# XMC4700 register map
Vendor: Infineon; File version: 1.3.0 (Reference Manual v1.3)
CPU: CM4 r2p0, little endian, MPU, FPU, 6 interrupt priority bits
Registers are 32-bit, read-write, reset 0x0 unless marked. A register's access mark holds for its fields unless they carry their own. Offsets are from the block's base; [hi:lo] are bit positions; {n}, {i} and the like mark numbered series.

## CAN — Controller Area Networks
Base 0x48014000
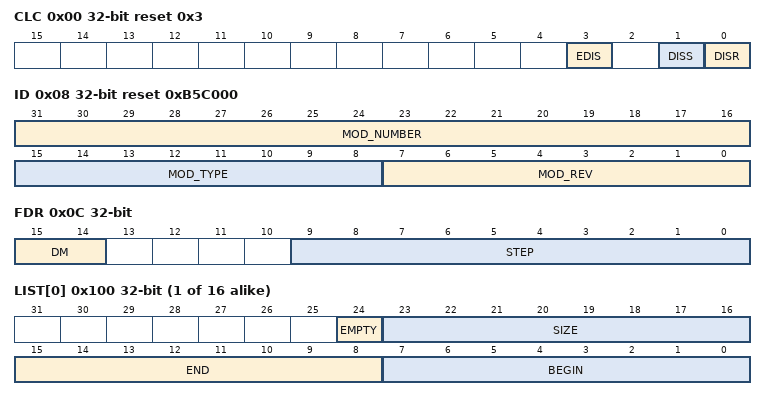
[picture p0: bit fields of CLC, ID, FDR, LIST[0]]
0x00 CLC access per field reset 0x3 — CAN Clock Control Register
  [3] EDIS rw — Sleep Mode Enable Control
  [1] DISS ro — Module Disable Status Bit
  [0] DISR rw — Module Disable Request Bit
0x08 ID ro reset 0xB5C000 (reset mask 0xFFFFFF00) — Module Identification Register
  [31:16] MOD_NUMBER — Module Number Value
  [15:8] MOD_TYPE — Module Type
    192=Define the module as a 32-bit module
  [7:0] MOD_REV — Module Revision Number
0x0C FDR — CAN Fractional Divider Register
  [15:14] DM — Divider Mode
  [9:0] STEP — Step Value
{0x100+4i} LIST[{i}] (i=0..15) ro reset not defined
  [24] EMPTY — List Empty Indication
    0=At least one message object is allocated to list i; 1=No message object is allocated to the list i. List i is empty.
  [23:16] SIZE — List Size
  [15:8] END — List End
  [7:0] BEGIN — List Begin
{0x140+4i} MSPND[{i}] (i=0..7) — Message Pending Register
  [31:0] PND — Message Pending
{0x180+4i} MSID[{i}] (i=0..7) ro reset 0x20 — Message Index Register
  [5:0] INDEX — Message Pending Index
0x1C0 MSIMASK — Message Index Mask Register
  [31:0] IM — Message Index Mask
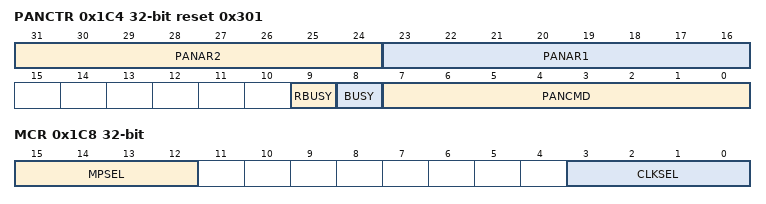
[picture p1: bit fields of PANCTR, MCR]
0x1C4 PANCTR access per field reset 0x301 — Panel Control Register
  [31:24] PANAR2 rw — Panel Argument 2
  [23:16] PANAR1 rw — Panel Argument 1
  [9] RBUSY ro — Result Busy Flag
    0=No update of PANAR1 and PANAR2 is scheduled by the list controller; 1=A list command is running (BUSY = 1) that will write results to PANAR1 and PANAR2, but the results are not yet available
  [8] BUSY ro — Panel Busy Flag
    0=Panel has finished command and is ready to accept a new command; 1=Panel operation is in progress
  [7:0] PANCMD rw — Panel Command
0x1C8 MCR — Module Control Register
  [15:12] MPSEL — Message Pending Selector
  [3:0] CLKSEL — Baud Rate Logic Clock Select
    0=No clock supplied; 1=fPERIPH; 2=fOHP; 4=hard wired to 0; 8=hard wired to 0
0x1CC MITR wo — Module Interrupt Trigger Register
  [7:0] IT — Interrupt Trigger

## DSD — Delta Sigma Demodulator
Base 0x40008000
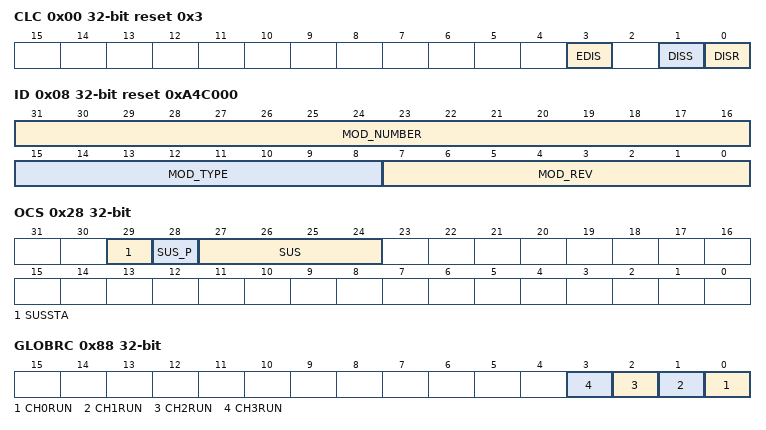
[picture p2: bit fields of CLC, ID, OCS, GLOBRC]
0x00 CLC access per field reset 0x3 — Clock Control Register
  [3] EDIS rw — Sleep Mode Enable Control
    0=Sleep mode request is enabled and functional; 1=Module disregards the sleep mode control signal
  [1] DISS ro — Module Disable Status Bit
    0=Module clock is enabled; 1=Off: module is not clocked
  [0] DISR rw — Module Disable Request Bit
    0=On request: enable the module clock; 1=Off request: stop the module clock
0x08 ID ro reset 0xA4C000 (reset mask 0xFFFFFF00) — Module Identification Register
  [31:16] MOD_NUMBER — Module Number
  [15:8] MOD_TYPE — Module Type
  [7:0] MOD_REV — Module Revision
0x28 OCS access per field — OCDS Control and Status Register
  [29] SUSSTA ro — Suspend State
    0=Module is not (yet) suspended; 1=Module is suspended
  [28] SUS_P wo — SUS Write Protection
  [27:24] SUS rw — OCDS Suspend Control
    0=Will not suspend; 1=Hard suspend: Clock is switched off immediately; 2=Soft suspend channel 0; 3=Soft suspend channel 1; 5=Soft suspend channel 3
0x80 GLOBCFG — Global Configuration Register
  [2:0] MCSEL — Modulator Clock Select
    0=Internal clock off, no source selected; 1=fDSD
0x88 GLOBRC — Global Run Control Register
  [all] fields
    0=Stop channel x; 1=Demodulator channel x is enabled and runs
  [n] CH{n}RUN (n=0..3) — Channel {n} Run Control
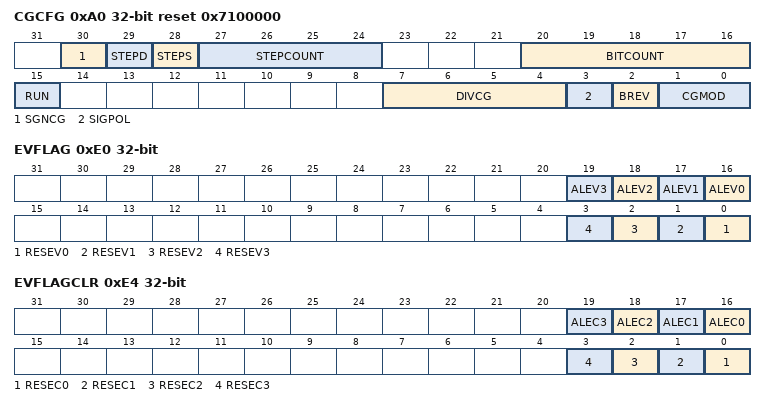
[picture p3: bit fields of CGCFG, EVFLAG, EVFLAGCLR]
0xA0 CGCFG access per field reset 0x7100000 — Carrier Generator Configuration Register
  [30] SGNCG ro — Sign Signal from Carrier Generator
    0=Positive values; 1=Negative values
  [29] STEPD ro — Step Counter Direction
    0=Step counter is counting up; 1=Step counter is counting down
  [28] STEPS ro — Step Counter Sign
    0=Step counter value is positive; 1=Step counter value is negative
  [27:24] STEPCOUNT ro — Step Counter
  [20:16] BITCOUNT ro — Bit Counter
  [15] RUN ro — Run Indicator
    0=Stopped (cleared at the end of a period); 1=Running
  [7:4] DIVCG rw — Divider Factor for the PWM Pattern Signal Generator
    0=fCG = fCLK / 2; 1=fCG = fCLK / 4; 2=fCG = fCLK / 6; 15=fCG = fCLK / 32
  [3] SIGPOL rw — Signal Polarity
    0=Normal: carrier signal begins with +1; 1=Inverted: carrier signal begins with -1
  [2] BREV rw — Bit-Reverse PWM Generation
    0=Normal mode; 1=Bit-reverse mode
  [1:0] CGMOD rw — Carrier Generator Operating Mode
    0=Stopped; 1=Square wave; 2=Triangle; 3=Sine wave
0xE0 EVFLAG — Event Flag Register
  [n+16] ALEV{n} (n=0..3) — Alarm Event
    0=No alarm event; 1=An alarm event has occurred
  [n] RESEV{n} (n=0..3) — Result Event
    0=No result event; 1=A new result has been stored in register RESMx
0xE4 EVFLAGCLR wo — Event Flag Clear Register
  [n+16] ALEC{n} (n=0..3) — Alarm Event Clear
    0=No action; 1=Clear bit ALEVx
  [n] RESEC{n} (n=0..3) — Result Event Clear
    0=No action; 1=Clear bit RESEVx

## CCU40 — Capture Compare Unit 4 - Unit 0
Base 0x4000C000
Same registers: CCU41 0x40010000, CCU42 0x40014000, CCU43 0x48004000
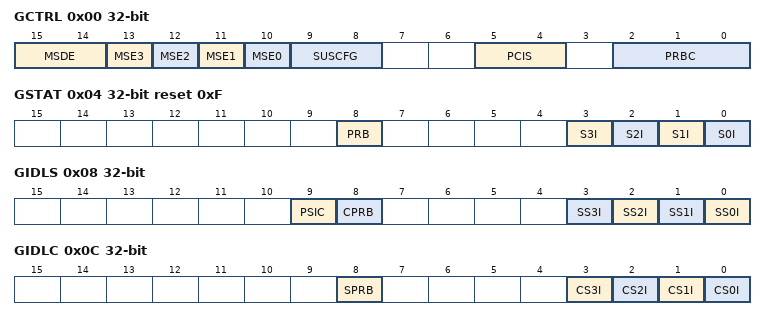
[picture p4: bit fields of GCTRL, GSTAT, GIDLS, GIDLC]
0x00 GCTRL — Global Control Register
  [15:14] MSDE — Multi Channel shadow transfer request configuration
    0=Only the shadow transfer for period and compare values is requested; 1=Shadow transfer for the compare, period and prescaler compare values is requested; 3=Shadow transfer for the compare, period, prescaler and dither compare values is requested
  [n+10] MSE{n} (n=0..3) — Slice {n} Multi Channel shadow transfer enable
    0=Shadow transfer can only be requested by SW; 1=Shadow transfer can be requested via SW and via the CCU4x.MCSS input
  [9:8] SUSCFG — Suspend Mode Configuration
    0=Suspend request ignored. The module never enters in suspend; 1=Stops all the running slices immediately. Safe stop is not applied.; 2=Stops the block immediately and clamps all the outputs to PASSIVE state. Safe stop is applied.; 3=Waits for the roll over of each slice to stop and clamp the slices outputs. Safe stop is applied.
  [5:4] PCIS — Prescaler Input Clock Selection
    0=Module clock; 1=CCU4x.ECLKA; 2=CCU4x.ECLKB; 3=CCU4x.ECLKC
  [2:0] PRBC — Prescaler Clear Configuration
    0=SW only; {v}=GSTATThe register contains the status of the prescaler and each timer slice (idle mode or running)..PRB and prescaler registers are cleared when the Run Bit of CC{v+39} is cleared (v=1..4)
0x04 GSTAT ro reset 0xF — Global Status Register
  [8] PRB — Prescaler Run Bit
    0=Prescaler is stopped; 1=Prescaler is running
  [n] S{n}I (n=0..3) — CC{n+40} IDLE status
    0=Running; 1=Idle
0x08 GIDLS wo — Global Idle Set
  [9] PSIC — Prescaler clear
  [8] CPRB — Prescaler Run Bit Clear
  [n] SS{n}I (n=0..3) — CC{n+40} IDLE mode set
0x0C GIDLC wo — Global Idle Clear
  [8] SPRB — Prescaler Run Bit Set
  [n] CS{n}I (n=0..3) — CC{n+40} IDLE mode clear
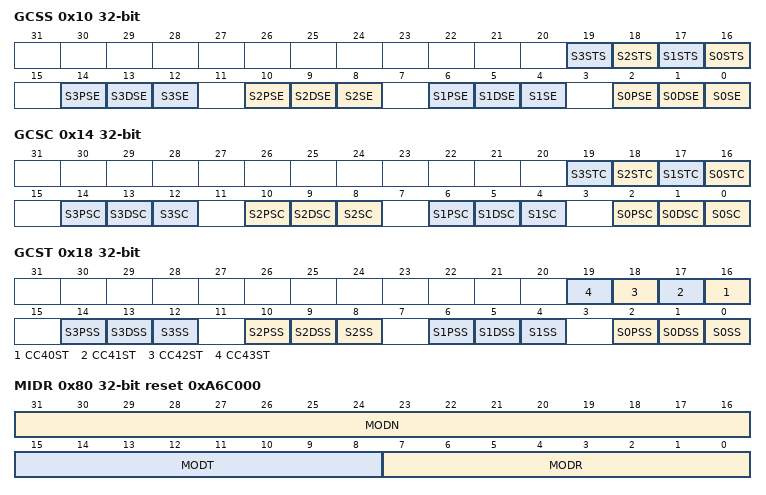
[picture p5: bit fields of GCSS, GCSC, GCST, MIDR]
0x10 GCSS wo — Global Channel Set
  [n+16] S{n}STS (n=0..3) — Slice {n} status bit set
  [4n+2] S{n}PSE (n=0..3) — Slice {n} Prescaler shadow transfer set enable
  [4n+1] S{n}DSE (n=0..3) — Slice {n} Dither shadow transfer set enable
  [4n] S{n}SE (n=0..3) — Slice {n} shadow transfer set enable
0x14 GCSC wo — Global Channel Clear
  [n+16] S{n}STC (n=0..3) — Slice {n} status bit clear
  [4n+2] S{n}PSC (n=0..3) — Slice {n} Prescaler shadow transfer clear
  [4n+1] S{n}DSC (n=0..3) — Slice {n} Dither shadow transfer clear
  [4n] S{n}SC (n=0..3) — Slice {n} shadow transfer clear
0x18 GCST ro — Global Channel Status
  [n-24] CC{n}ST (n=40..43) — Slice {n-40} status bit
  [4n+2] S{n}PSS (n=0..3) — Slice {n} Prescaler shadow transfer status
    0=Prescaler shadow transfer has not been requested; 1=Prescaler shadow transfer has been requested
  [4n+1] S{n}DSS (n=0..3) — Slice {n} Dither shadow transfer status
    0=Dither shadow transfer has not been requested; 1=Dither shadow transfer has been requested
  [4n] S{n}SS (n=0..3) — Slice {n} shadow transfer status
    0=Shadow transfer has not been requested; 1=Shadow transfer has been requested
0x80 MIDR ro reset 0xA6C000 (reset mask 0xFFFFFF00) — Module Identification
  [31:16] MODN — Module Number
  [15:8] MODT — Module Type
  [7:0] MODR — Module Revision
